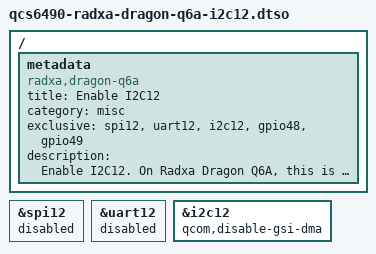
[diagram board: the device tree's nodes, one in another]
// SPDX-License-Identifier: BSD-3-Clause
/*
 * Copyright (c) 2025 Radxa Computer (Shenzhen) Co., Ltd.
 */

/dts-v1/;
/plugin/;

/ {
    metadata {
        title = "Enable I2C12";
        compatible = "radxa,dragon-q6a";
        category = "misc";
        exclusive = "spi12", "uart12", "i2c12", "gpio48", "gpio49";
        description = "Enable I2C12.
On Radxa Dragon Q6A, this is pin 19(scl), 21(sda).";
    };
};

&spi12 {
	status = "disabled";
};

&uart12 {
	status = "disabled";
};

&i2c12 {
	qcom,disable-gsi-dma;
	status = "okay";
};
